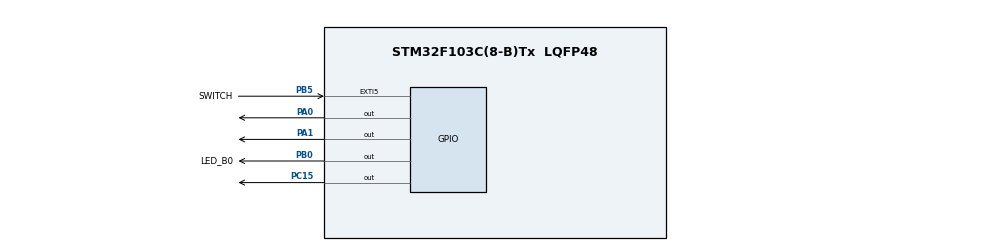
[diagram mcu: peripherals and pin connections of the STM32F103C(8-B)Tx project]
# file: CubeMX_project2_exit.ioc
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Mcu.Family=STM32F1
Mcu.Name=STM32F103C(8-B)Tx
Mcu.Package=LQFP48
NVIC.EXTI9_5_IRQn=true\:0\:0\:false\:false\:true\:true\:true
NVIC.PriorityGroup=NVIC_PRIORITYGROUP_4
PA0-WKUP.PinState=GPIO_PIN_RESET
PA0-WKUP.Signal=GPIO_Output
PA1.PinState=GPIO_PIN_SET
PA1.Signal=GPIO_Output
PA13.Mode=Serial_Wire
PA13.Signal=SYS_JTMS-SWDIO
PA14.Mode=Serial_Wire
PA14.Signal=SYS_JTCK-SWCLK
PB0.GPIO_Label=LED_B0
PB0.Signal=GPIO_Output
PB5.GPIO_Label=SWITCH
PB5.GPIO_ModeDefaultEXTI=GPIO_MODE_IT_RISING_FALLING
PB5.Signal=GPXTI5
PC15-OSC32_OUT.Signal=GPIO_Output
ProjectManager.HeapSize=0x200
ProjectManager.StackSize=0x400
ProjectManager.TargetToolchain=MDK-ARM V5
RCC.APB1Freq_Value=8000000
RCC.APB2Freq_Value=8000000
board=custom

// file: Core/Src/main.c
/* USER CODE BEGIN Header */
/**
  ******************************************************************************
  * @file           : main.c
  * @brief          : Main program body
  ******************************************************************************
  * @attention
  *
  * <h2><center>&copy; Copyright (c) 2025 STMicroelectronics.
  * All rights reserved.</center></h2>
  *
  * This software component is licensed by ST under BSD 3-Clause license,
  * the "License"; You may not use this file except in compliance with the
  * License. You may obtain a copy of the License at:
  *                        opensource.org/licenses/BSD-3-Clause
  *
  ******************************************************************************
  */
/* USER CODE END Header */
#include "main.h"
#include "gpio.h"

void SystemClock_Config(void);

int main(void)
{

  /* MCU Configuration--------------------------------------------------------*/

  /* Reset of all peripherals, Initializes the Flash interface and the Systick. */
  HAL_Init();

  /* Configure the system clock */
  SystemClock_Config();

  /* Initialize all configured peripherals */
  MX_GPIO_Init();
  /* USER CODE BEGIN 2 */
  // 初始化状态：A0输出低电平，A1输出高电平
  HAL_GPIO_WritePin(GPIOA, GPIO_PIN_0, GPIO_PIN_RESET);  // A0低电平
  HAL_GPIO_WritePin(GPIOA, GPIO_PIN_1, GPIO_PIN_SET);    // A1高电平

  // 初始状态：B0 LED熄灭（低电平熄灭）
  HAL_GPIO_WritePin(GPIOB, GPIO_PIN_0, GPIO_PIN_RESET);  // B0灭（低电平）
  /* USER CODE END 2 */

  /* Infinite loop */
  while (1)
  {

    /* USER CODE BEGIN 3 */
    // 主循环可以空着，中断会处理LED控制
  }
  /* USER CODE END 3 */
}

void SystemClock_Config(void)
{
  RCC_OscInitTypeDef RCC_OscInitStruct = {0};
  RCC_ClkInitTypeDef RCC_ClkInitStruct = {0};

  /** Initializes the RCC Oscillators according to the specified parameters
  * in the RCC_OscInitTypeDef structure.
  */
  RCC_OscInitStruct.OscillatorType = RCC_OSCILLATORTYPE_HSI;
  RCC_OscInitStruct.HSIState = RCC_HSI_ON;
  RCC_OscInitStruct.HSICalibrationValue = RCC_HSICALIBRATION_DEFAULT;
  RCC_OscInitStruct.PLL.PLLState = RCC_PLL_NONE;
  if (HAL_RCC_OscConfig(&RCC_OscInitStruct) != HAL_OK)
  {
    Error_Handler();
  }
  /** Initializes the CPU, AHB and APB buses clocks
  */
  RCC_ClkInitStruct.ClockType = RCC_CLOCKTYPE_HCLK|RCC_CLOCKTYPE_SYSCLK
                              |RCC_CLOCKTYPE_PCLK1|RCC_CLOCKTYPE_PCLK2;
  RCC_ClkInitStruct.SYSCLKSource = RCC_SYSCLKSOURCE_HSI;
  RCC_ClkInitStruct.AHBCLKDivider = RCC_SYSCLK_DIV1;
  RCC_ClkInitStruct.APB1CLKDivider = RCC_HCLK_DIV1;
  RCC_ClkInitStruct.APB2CLKDivider = RCC_HCLK_DIV1;

  if (HAL_RCC_ClockConfig(&RCC_ClkInitStruct, FLASH_LATENCY_0) != HAL_OK)
  {
    Error_Handler();
  }
}

/* USER CODE BEGIN 4 */
// 外部中断回调函数 - 低电平熄灭，高电平点亮
__weak void HAL_GPIO_EXTI_Callback(uint16_t GPIO_Pin)
{
    if(GPIO_Pin == GPIO_PIN_5)  // B5引脚的中断
    {
        // 获取B5的当前状态
        GPIO_PinState pinState = HAL_GPIO_ReadPin(GPIOB, GPIO_PIN_5);

        // 根据B5的状态控制B0 LED
        if(pinState == GPIO_PIN_RESET)  // 低电平
        {
            HAL_GPIO_WritePin(GPIOB, GPIO_PIN_0, GPIO_PIN_RESET);  // B0熄灭（低电平）
        }
        else  // 高电平
        {
            HAL_GPIO_WritePin(GPIOB, GPIO_PIN_0, GPIO_PIN_SET);    // B0点亮（高电平）
        }
    }
}
/* USER CODE END 4 */

void Error_Handler(void)
{
  __disable_irq();
  while (1)
  {
  }
}

/************************ (C) COPYRIGHT STMicroelectronics *****END OF FILE****/
